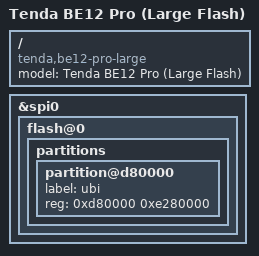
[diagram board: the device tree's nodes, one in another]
// SPDX-License-Identifier: GPL-2.0-or-later OR MIT

/dts-v1/;
#include "mt7987a-tenda-be12-pro.dts"

/ {
	model = "Tenda BE12 Pro (Large Flash)";
	compatible = "tenda,be12-pro-large", "tenda,be12-pro", "mediatek,mt7987a", "mediatek,mt7987";
};

&spi0 {
	flash@0 {
		partitions {
			/*
			 * Large-flash layout (256M / 512M retrofit chips).
			 *
			 * The ubi START offset is deliberately KEPT at 0xd80000: this board
			 * boots its stock u-boot, which locates the ubi volume at a
			 * hard-coded offset -- moving it would brick the device.
			 *
			 * Dropped trailing partitions: CFG, MISC2 (stock read-only blobs).
			 * ubi then spans to the 512MiB boundary; UBI truncates itself to
			 * the real chip size, so one image covers both 256M and 512M.
			 */
			partition@d80000 {
				label = "ubi";
				reg = <0xd80000 0xe280000>;
			};

			/delete-node/ partition@6780000;
			/delete-node/ partition@6b80000;
		};
	};
};
